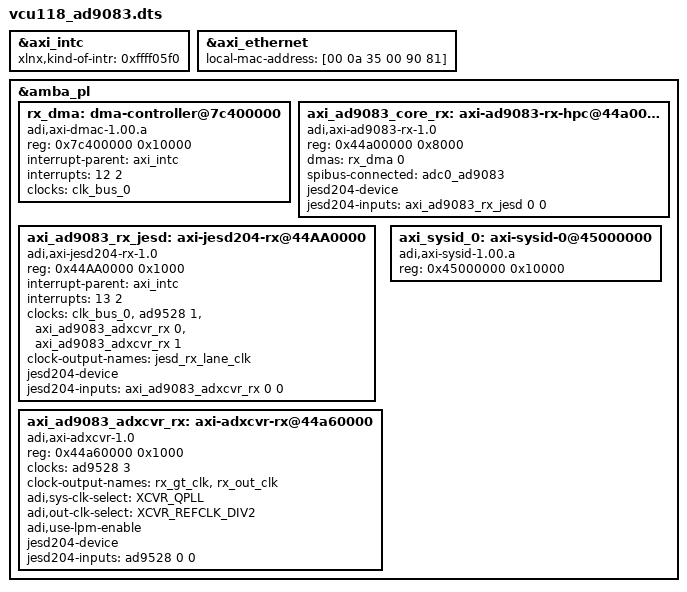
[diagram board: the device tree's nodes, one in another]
// SPDX-License-Identifier: GPL-2.0
/*
 * Analog Devices AD9083-EVB
 * Link: https://wiki.analog.com/resources/eval/ad9083
 *
 * Copyright (C) 2018-2026 Analog Devices Inc.
 */

/dts-v1/;

#include "vcu118.dtsi"
#include <dt-bindings/interrupt-controller/irq.h>
#include <dt-bindings/iio/adc/adi,ad9083.h>
#include <dt-bindings/gpio/gpio.h>
#include <dt-bindings/jesd204/adxcvr.h>

#define fmc_spi axi_spi

&axi_intc {
	xlnx,kind-of-intr = <0xffff05f0>;
};

&axi_ethernet {
	local-mac-address = [00 0a 35 00 90 81];
};

&amba_pl {

	rx_dma: dma-controller@7c400000 {
		compatible = "adi,axi-dmac-1.00.a";
		reg = <0x7c400000 0x10000>;
		#dma-cells = <1>;
		#clock-cells = <0>;
		interrupt-parent = <&axi_intc>;
		interrupts = <12 2>;
		clocks = <&clk_bus_0>;
	};

	axi_ad9083_core_rx: axi-ad9083-rx-hpc@44a00000 {
		compatible = "adi,axi-ad9083-rx-1.0";
		reg = <0x44a00000 0x8000>;
		dmas = <&rx_dma 0>;
		dma-names = "rx";
		spibus-connected = <&adc0_ad9083>;

		jesd204-device;
		#jesd204-cells = <2>;
		jesd204-inputs = <&axi_ad9083_rx_jesd 0 0>;
	};

	axi_ad9083_rx_jesd: axi-jesd204-rx@44AA0000 {
		compatible = "adi,axi-jesd204-rx-1.0";
		reg = <0x44AA0000 0x1000>;

		interrupt-parent = <&axi_intc>;
		interrupts = <13 2>;

		clocks = <&clk_bus_0>, <&ad9528 1>, <&axi_ad9083_adxcvr_rx 0>, <&axi_ad9083_adxcvr_rx 1>;
		clock-names = "s_axi_aclk", "device_clk", "lane_clk", "link_clk";

		#clock-cells = <0>;
		clock-output-names = "jesd_rx_lane_clk";

		jesd204-device;
		#jesd204-cells = <2>;
		jesd204-inputs = <&axi_ad9083_adxcvr_rx 0 0>;
	};

	axi_ad9083_adxcvr_rx: axi-adxcvr-rx@44a60000 {
		#address-cells = <1>;
		#size-cells = <0>;
		compatible = "adi,axi-adxcvr-1.0";
		reg = <0x44a60000 0x1000>;

		clocks = <&ad9528 3>;
		clock-names = "conv";

		#clock-cells = <1>;
		clock-output-names = "rx_gt_clk", "rx_out_clk";

		adi,sys-clk-select = <XCVR_QPLL>;
		adi,out-clk-select = <XCVR_REFCLK_DIV2>;
		adi,use-lpm-enable;

		jesd204-device;
		#jesd204-cells = <2>;
		jesd204-inputs = <&ad9528 0 0>;
	};

	axi_sysid_0: axi-sysid-0@45000000 {
		compatible = "adi,axi-sysid-1.00.a";
		reg = <0x45000000 0x10000>;
	};
};

#include "adi-ad9083-fmc-ebz.dtsi"
